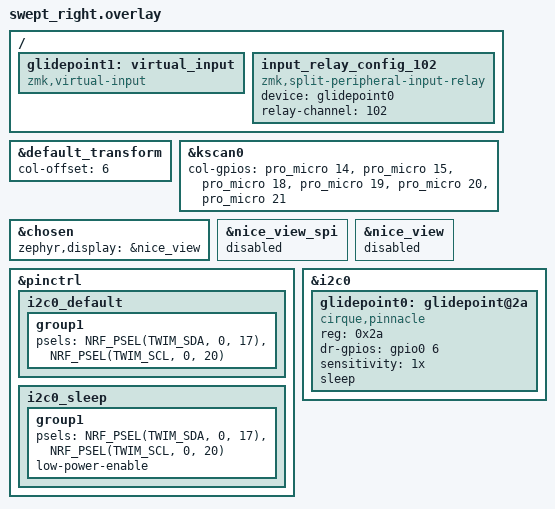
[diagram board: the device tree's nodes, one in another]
/*
 * Copyright (c) 2022 The ZMK Contributors
 *
 * SPDX-License-Identifier: MIT
 */

#include "swept.dtsi"

&default_transform {
  col-offset = <6>;
};

&kscan0 {
  col-gpios
    = <&pro_micro 14 GPIO_ACTIVE_HIGH>
    , <&pro_micro 15 GPIO_ACTIVE_HIGH>
    , <&pro_micro 18 GPIO_ACTIVE_HIGH>
    , <&pro_micro 19 GPIO_ACTIVE_HIGH>
    , <&pro_micro 20 GPIO_ACTIVE_HIGH>
    , <&pro_micro 21 GPIO_ACTIVE_HIGH>
    ;
};

&chosen {
  zephyr,display = &nice_view;
};

// nice view bus
&nice_view_spi {
  status = "disable";
};

&nice_view {
  status = "disable";
};

&pinctrl {  
  i2c0_default: i2c0_default {
    group1 {
      psels = <NRF_PSEL(TWIM_SDA, 0, 17)>,
          <NRF_PSEL(TWIM_SCL, 0, 20)>;
    };
  };

  i2c0_sleep: i2c0_sleep {
    group1 {
      psels = <NRF_PSEL(TWIM_SDA, 0, 17)>,
          <NRF_PSEL(TWIM_SCL, 0, 20)>;
      low-power-enable;
    };
  };
};

&i2c0 {
    status = "okay";
    glidepoint0: glidepoint@2a {
        compatible = "cirque,pinnacle";
        reg = <0x2a>;
        status = "okay";
        dr-gpios = <&gpio0 6 (GPIO_ACTIVE_HIGH)>;

        sensitivity = "1x";
        sleep;
        // no-taps;
    };

};

/ {
    /* THIS only makes keymap binding happy, nothing happens on peripheral side */
	glidepoint1: virtual_input {
		compatible = "zmk,virtual-input";
	};

    input_relay_config_102 {
        compatible = "zmk,split-peripheral-input-relay";

        /* peripheral side input device, used to... */
		/*  - be intecepted on peripheral; */
		/*  - and then, be resurrected as `zmk,virtual-device` on central; */
        device = <&glidepoint0>;

        /* channel id, used to be be transfered along with all input events. */
		/* NOTE 1: pick any 8bit integer. (1 - 255) */
		/* NOTE 2: should matching relay-channel on central overlay */
		relay-channel = <102>;
    };
};
